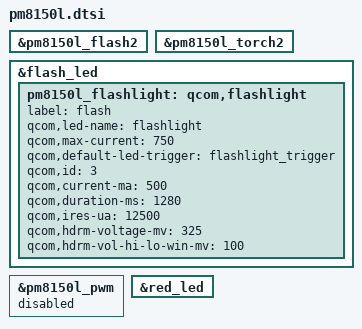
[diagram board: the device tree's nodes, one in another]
&pm8150l_flash2 {
	status = "ok";
};

&pm8150l_torch2 {
	status = "ok";
};

&flash_led {
	pm8150l_flashlight: qcom,flashlight {
		label = "flash";
		qcom,led-name = "flashlight";
		qcom,max-current = <750>;
		qcom,default-led-trigger = "flashlight_trigger";
		qcom,id = <3>;
		qcom,current-ma = <500>;
		qcom,duration-ms = <1280>;
		qcom,ires-ua = <12500>;
		qcom,hdrm-voltage-mv = <325>;
		qcom,hdrm-vol-hi-lo-win-mv = <100>;
	};
};

&pm8150l_pwm {
	status = "disabled";
};

&red_led {
	/delete-property/ linux,default-trigger;
};
